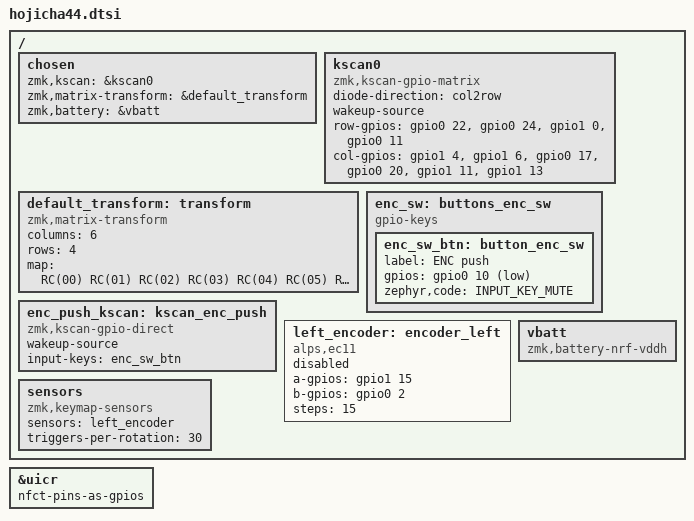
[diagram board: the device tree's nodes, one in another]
/*
 * Hojicha44 shared devicetree — DRAFT, not yet compiled against a ZMK tree.
 *
 * Covers both halves: 4x6 matrix (R3C4-C5 unpopulated), EC11 on A0/A1 with
 * push on D16, VDDH battery sensing, NFC pins as GPIO. Per-half differences
 * (none for kscan/UART — see hojicha44_{left,right}.overlay) live in the
 * half overlays. UART pinctrl is IDENTICAL on both halves: the TX/RX
 * crossover for the straight TRRS cable is done in copper (right half wires
 * D1->RING1, D0->TIP), so both MCUs use TX=P0.06 RX=P0.08.
 *
 * Verify with: west build -b nice_nano_v2 -- -DSHIELD=hojicha44_left
 * (needs a zmk-config wrapper providing the shield + board files).
 */

#include <dt-bindings/zmk/matrix_transform.h>
#include <zephyr/dt-bindings/input/input-event-codes.h>

/ {
    chosen {
        zmk,kscan = &kscan0;
        zmk,matrix-transform = &default_transform;
        zmk,battery = &vbatt;
    };

    kscan0: kscan0 {
        compatible = "zmk,kscan-gpio-matrix";
        diode-direction = "col2row";
        wakeup-source;
        /* row-gpios / col-gpios are half-specific only in net NAME;
         * the Arduino pins are identical, so they live here. */
        row-gpios
            = <&gpio0 22 (GPIO_ACTIVE_HIGH | GPIO_PULL_DOWN)>    /* R0 = D4  */
            , <&gpio0 24 (GPIO_ACTIVE_HIGH | GPIO_PULL_DOWN)>    /* R1 = D5  */
            , <&gpio1  0 (GPIO_ACTIVE_HIGH | GPIO_PULL_DOWN)>    /* R2 = D6  */
            , <&gpio0 11 (GPIO_ACTIVE_HIGH | GPIO_PULL_DOWN)>;   /* R3 = D7  */
        col-gpios
            = <&gpio1  4 GPIO_ACTIVE_HIGH>      /* C0 = D8  */
            , <&gpio1  6 GPIO_ACTIVE_HIGH>      /* C1 = D9  */
            , <&gpio0 17 GPIO_ACTIVE_HIGH>      /* C2 = D2  */
            , <&gpio0 20 GPIO_ACTIVE_HIGH>      /* C3 = D3  */
            , <&gpio1 11 GPIO_ACTIVE_HIGH>      /* C4 = D14 */
            , <&gpio1 13 GPIO_ACTIVE_HIGH>;     /* C5 = D15 */
    };

    default_transform: transform {
        compatible = "zmk,matrix-transform";
        columns = <6>;
        rows = <4>;
        map = <
            RC(00) RC(01) RC(02) RC(03) RC(04) RC(05)
            RC(10) RC(11) RC(12) RC(13) RC(14) RC(15)
            RC(20) RC(21) RC(22) RC(23) RC(24) RC(25)
            RC(30) RC(31) RC(32) RC(33) RC(34) RC(35)
        >;
    };

    enc_sw: buttons_enc_sw {
        compatible = "gpio-keys";
        /* EC11 push is a dedicated GPIO (D16 = P0.10), not matrixed.
         * Shape per the Zephyr gpio-keys binding: one child node per
         * button carrying `gpios` (+ optional `label`/`zephyr,code`) —
         * a parent-level `sw-gpios` property does not exist.
         * S1 closes to GND, so ACTIVE_LOW with pull-up.
         * ZMK-docs discrepancy note: ZMK keymaps consume *kscan* events,
         * not Zephyr input events (zmk.dev/docs/features/encoders says a
         * push is "typically" part of the keyboard matrix). This node only
         * corrects the pin description; the keymap path is the direct
         * kscan below, consumed by the sideband in hojicha44.keymap.
         * Binding source: docs.zephyrproject.org/latest/build/dts/api/
         * bindings/input/gpio-keys.html */
        enc_sw_btn: button_enc_sw {
            label = "ENC push";
            gpios = <&gpio0 10 (GPIO_ACTIVE_LOW | GPIO_PULL_UP)>;
            zephyr,code = <INPUT_KEY_MUTE>;
        };
    };

    enc_push_kscan: kscan_enc_push {
        /* ZMK-supported keymap path for the dedicated-GPIO push: direct
         * kscan over the gpio-key above (`input-keys` takes gpio-key
         * phandles; the single key emits row 0 / column 0 events).
         * Consumed by the sideband in hojicha44.keymap; the chosen kscan
         * stays kscan0, so the 24-cell matrix path is untouched.
         * Binding source: zmk.dev/docs/config/kscan (Direct GPIO driver)
         * + app/module/drivers/kscan/kscan_gpio_direct.c in zmkfirmware/zmk
         * (`input-keys`, events at row 0 / column index). */
        compatible = "zmk,kscan-gpio-direct";
        wakeup-source;
        input-keys = <&enc_sw_btn>;
    };

    left_encoder: encoder_left {
        /* Shared node: defined ONCE here, enabled per-half by each overlay's
           &left_encoder { status = "okay"; } and consumed by sensors below.
           The name is NOT a left-half leak — do NOT rename per half. */
        compatible = "alps,ec11";
        a-gpios = <&gpio1 15 (GPIO_ACTIVE_HIGH | GPIO_PULL_UP)>;  /* A0 */
        b-gpios = <&gpio0  2 (GPIO_ACTIVE_HIGH | GPIO_PULL_UP)>;  /* A1 */
        steps = <15>;             /* EC11E15244G1: 30 detents but 15 PULSES/rev;
                                   ZMK `steps` counts pulses per revolution —
                                   confirm CW/CCW event counts over one full
                                   revolution on first article */
        status = "disabled";      /* enabled per half-overlay */
    };

    sensors: sensors {
        compatible = "zmk,keymap-sensors";
        sensors = <&left_encoder>;
        triggers-per-rotation = <30>;
    };

    vbatt: vbatt {
        compatible = "zmk,battery-nrf-vddh";
    };
};

/* P0.09 (D10) and P0.10 (D16/ENC push) are NFC pins: take them as GPIO.
 * UICR is sticky — full chip erase required to apply or clear. */
&uicr {
    nfct-pins-as-gpios;
};
